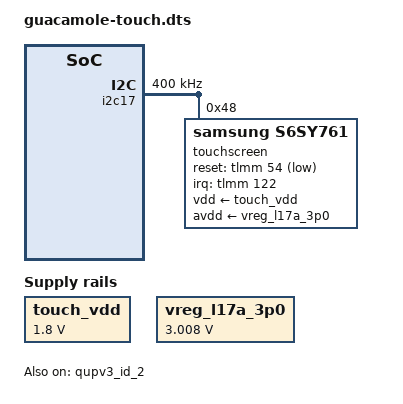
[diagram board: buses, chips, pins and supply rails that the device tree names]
/dts-v1/;
/plugin/;

/* Guacamole wiring from OnePlus 18821 downstream sm8150-oem.dtsi.
 * The 7T Pro uses different supply rails; do not substitute its AVDD.
 * Only enables touch dependencies; GPU/USB/display nodes are untouched.
 */
&{/} {
    touch_vdd: regulator-touch-vdd {
        compatible = "regulator-fixed";
        regulator-name = "touch-vdd-1p8";
        regulator-min-microvolt = <1800000>;
        regulator-max-microvolt = <1800000>;
        pinctrl-names = "default";
        pinctrl-0 = <&tp_1v8_active>;
    };
};

&tlmm {
    touch_reset: touch-reset-state {
        pins = "gpio54";
        function = "gpio";
        drive-strength = <8>;
        bias-disable;
    };
};

&vreg_l17a_3p0 {
    regulator-min-microvolt = <3008000>;
    regulator-max-microvolt = <3008000>;
};

&gpi_dma2 { status = "okay"; };
&qupv3_id_2 { status = "okay"; };
&i2c17 {
    status = "okay";
    clock-frequency = <400000>;
    #address-cells = <1>;
    #size-cells = <0>;
    touchscreen@48 {
        compatible = "samsung,s6sy761";
        reg = <0x48>;
        interrupt-parent = <&tlmm>;
        interrupts = <122 8>; /* IRQ_TYPE_LEVEL_LOW */
        vdd-supply = <&touch_vdd>;
        avdd-supply = <&vreg_l17a_3p0>;
        reset-gpios = <&tlmm 54 1>; /* GPIO_ACTIVE_LOW */
        pinctrl-names = "default";
        pinctrl-0 = <&touch_reset &tp_irq_active>;
        touchscreen-size-x = <1440>;
        touchscreen-size-y = <3120>;
    };
};
